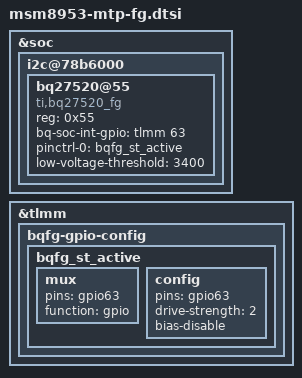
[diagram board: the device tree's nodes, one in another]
/*
 * Copyright (c) 2015-2016, The Linux Foundation. All rights reserved.
 *
 * This program is free software; you can redistribute it and/or modify
 * it under the terms of the GNU General Public License version 2 and
 * only version 2 as published by the Free Software Foundation.
 *
 * This program is distributed in the hope that it will be useful,
 * but WITHOUT ANY WARRANTY; without even the implied warranty of
 * MERCHANTABILITY or FITNESS FOR A PARTICULAR PURPOSE.  See the
 * GNU General Public License for more details.
 */

&soc {
	i2c@78b6000 { /* BLSP1 QUP5 */
		bq27520@55 {
			compatible = "ti,bq27520_fg";
			reg = <0x55>;
			bq-soc-int-gpio = <&tlmm 63 0x00>;
			pinctrl-names = "default";
     		pinctrl-0 = <&bqfg_st_active>;
			low-voltage-threshold = <3400>;
		};
	};
};

&tlmm {
	bqfg-gpio-config {
        bqfg_st_active: bqfg_st_active {
			mux {
				pins = "gpio63";
				function = "gpio";
			};

			config {
				pins = "gpio63";
				drive-strength = <2>;
				bias-disable;
			};
		};
	};
};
